# ESP32-S31 register map
Vendor: ESPRESSIF SYSTEMS (SHANGHAI) CO., LTD.; Series: ESP32 S-Series; File version: 1
CPU: RV32IMAFC r0p0, little endian, no MPU, FPU, 0 interrupt priority bits
Address unit: 32 bits
Registers are 32-bit, read-write, reset 0x0 unless marked. A register's access mark holds for its fields unless they carry their own. Offsets are from the block's base; [hi:lo] are bit positions; {n}, {i} and the like mark numbered series; <NAME> marks a mode.

## AES — AES (Advanced Encryption Standard) Accelerator
Base 0x20508000
{0x0+4i} KEY_{i} (i=0..7) — AES key data register {i}
  [31:0] KEY_0 — This bits stores key_0 that is a part of key material.
{0x20+4i} TEXT_IN_{i} (i=0..3) — Source text data register {i}
  [31:0] TEXT_IN_0 — This bits stores text_in_0 that is a part of source text material.
{0x30+4i} TEXT_OUT_{i} (i=0..3) — Result text data register {i}
  [31:0] TEXT_OUT_0 — This bits stores text_out_0 that is a part of result text material.
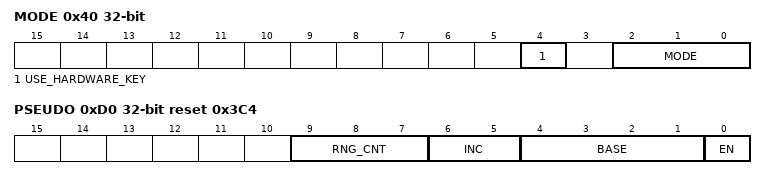
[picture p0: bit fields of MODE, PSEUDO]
0x40 MODE — Defines key length and encryption / decryption
  [4] USE_HARDWARE_KEY — Configures the AES accelerator use software key or hardware key.\\ 0: Software key. \\ 1: Hardware key. \\
  [2:0] MODE — Configures the key length and encryption / decryption of the AES accelerator.\\ 0: AES-128 encryption\\ 1: AES-192 encryption\\ 2: AES-256 encryption\\ 3: Reserved\\ 4: AES-128 decryption\\ 5: AES-192 decryption\\ 6: AES-256 decryption\\ 7: Reserved\\
0x44 ENDIAN — AES Endian configure register
  [5:0] ENDIAN — endian. [1:0] key endian, [3:2] text_in endian or in_stream endian, [5:4] text_out endian or out_stream endian
0x48 TRIGGER wo — Operation start controlling register
  [0] TRIGGER — Configures whether or not to start AES operation. \\ 0: No effect\\ 1: Start\\
0x4C STATE ro — Operation status register
  [1:0] STATE — Represents the working status of the AES accelerator. \\ In Typical AES working mode:\\ 0: IDLE\\ 1: WORK\\ 2: No effect\\ 3: No effect\\ In DMA-AES working mode:\\ 0: IDLE\\ 1: WORK\\ 2: DONE\\ 3: No effect\\
{0x50+i} IV_MEM[{i}] (i=0..15) 8-bit access not given — The memory that stores initialization vector
{0x60+i} H_MEM[{i}] (i=0..15) 8-bit access not given — The memory that stores GCM hash subkey
{0x70+i} J0_MEM[{i}] (i=0..15) 8-bit access not given — The memory that stores J0
{0x80+i} T0_MEM[{i}] (i=0..15) 8-bit access not given — The memory that stores T0
0x90 DMA_ENABLE — Selects the working mode of the AES accelerator
  [0] DMA_ENABLE — Configures the working mode of the AES accelerator. \\ 0: Typical AES\\ 1: DMA-AES\\
0x94 BLOCK_MODE — Defines the block cipher mode
  [2:0] BLOCK_MODE — Configures the block cipher mode of the AES accelerator operating under the DMA-AES working mode. \\ 0: ECB (Electronic Code Block)\\ 1: CBC (Cipher Block Chaining)\\ 2: OFB (Output FeedBack)\\ 3: CTR (Counter)\\ 4: CFB8 (8-bit Cipher FeedBack)\\ 5: CFB128 (128-bit Cipher FeedBack)\\ 6: GCM\\ 7: Reserved\\
0x98 BLOCK_NUM — Block number configuration register
  [31:0] BLOCK_NUM — Represents the Block Number of plaintext or ciphertext when the AES accelerator operates under the DMA-AES working mode. For details, see Section <a href=sec:aes-block-number">link</a>. "
0x9C INC_SEL — Standard incrementing function register
  [0] INC_SEL — Configures the Standard Incrementing Function for CTR block operation. \\ 0: INC<SUB>32</SUB>\\ 1: INC<SUB>128</SUB>\\
0xA0 AAD_BLOCK_NUM — Additional Authential Data block number register
  [31:0] AAD_BLOCK_NUM — Those bits stores the number of AAD block.
0xA4 REMAINDER_BIT_NUM — AES remainder bit number register
  [6:0] REMAINDER_BIT_NUM — Those bits stores the number of remainder bit.
0xA8 CONTINUE wo — AES continue register
  [0] CONTINUE — Set this bit to continue GCM operation.
0xAC INT_CLEAR wo — DMA-AES interrupt clear register
  [0] INT_CLEAR — Configures whether or not to clear AES interrupt. \\ 0: No effect \\ 1: Clear \\
0xB0 INT_ENA — DMA-AES interrupt enable register
  [0] INT_ENA — Configures whether or not to enable AES interrupt.\\ 0: Disable\\ 1: Enable \\
0xB4 DATE reset 0x2507280 — AES version control register
  [27:0] DATE — This bits stores the version information of AES.
0xB8 DMA_EXIT wo — Operation exit controlling register
  [0] DMA_EXIT — Configures whether or not to exit AES operation. \\ 0: No effect\\ 1: Exit\\ Only valid for DMA-AES operation.
0xC0 RX_RESET wo — AES-DMA reset rx-fifo register
  [0] RX_RESET — Set this bit to reset rx_fifo under dma_aes working mode.
0xC4 TX_RESET wo — AES-DMA reset tx-fifo register
  [0] TX_RESET — Set this bit to reset tx_fifo under dma_aes working mode.
0xD0 PSEUDO reset 0x3C4 — AES PSEUDO function configure register
  [9:7] RNG_CNT — Those bits decides the update frequency of the pseudo-key.
  [6:5] INC — Those bits decides the increment number of pseudo round number
  [4:1] BASE — Those bits decides the basic number of pseudo round number.
  [0] EN — This bit decides whether the pseudo round function is enable or not.
0xD4 FREE reset 0x1 — AES free state register
  [0] FREE — 0: AES is non-free; 1:AES is free.

## Notices in the file
Copyright 2026 Espressif Systems (Shanghai) PTE LTD
Licensed under the Apache License, Version 2.0 (the "License");
you may not use this file except in compliance with the License.
You may obtain a copy of the License at
http://www.apache.org/licenses/LICENSE-2.0
Unless required by applicable law or agreed to in writing, software
distributed under the License is distributed on an "AS IS" BASIS,
WITHOUT WARRANTIES OR CONDITIONS OF ANY KIND, either express or implied.
See the License for the specific language governing permissions and
limitations under the License.
